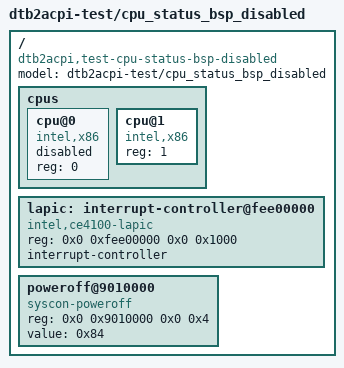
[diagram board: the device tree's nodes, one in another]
/dts-v1/;

/* cpu@0 is `status = "disabled"` while cpu@1 is `okay`. This is the
 * "BSP is hot-onlineable" misconfiguration — the hypervisor still
 * designates cpu@0 as the BSP at VM creation (universal convention),
 * but MADT would mark that cpu Enabled=0, which the BSP-as-itself
 * reads as self-contradictory at boot. count must surface
 * `BootCpuNotEnabled` even though cpu@1 is healthy.
 */

/ {
	#address-cells = <2>;
	#size-cells = <2>;
	model = "dtb2acpi-test/cpu_status_bsp_disabled";
	compatible = "dtb2acpi,test-cpu-status-bsp-disabled";

	cpus {
		#address-cells = <1>;
		#size-cells = <0>;

		cpu@0 {
			device_type = "cpu";
			reg = <0>;
			compatible = "intel,x86";
			status = "disabled";
		};

		cpu@1 {
			device_type = "cpu";
			reg = <1>;
			compatible = "intel,x86";
			/* status absent → "okay" */
		};
	};

		lapic: interrupt-controller@fee00000 {
		compatible = "intel,ce4100-lapic";
		reg = <0x0 0xfee00000 0x0 0x1000>;
		interrupt-controller;
		#interrupt-cells = <2>;
	};
		poweroff@9010000 {
		compatible = "syscon-poweroff";
		reg = <0x0 0x9010000 0x0 0x4>;
		value = <0x84>;
	};
};
